# CUSTEFUSE_CM_CORE register map
Vendor: Texas Instruments
Peripheral module from a debugger description file (folder omap5430_ES2_PUBLIC).
Registers are 32-bit, access per field, reset 0x3 unless marked. A register's access mark holds for its fields unless they carry their own. Offsets are as the file gives them; lines under a group give offsets from that group; [hi:lo] are bit positions; {n}, {i} and the like mark numbered series; 'fields as' and 'values as' point back to an identical list; <NAME> marks a mode.

## CUSTEFUSE_CM_CORE
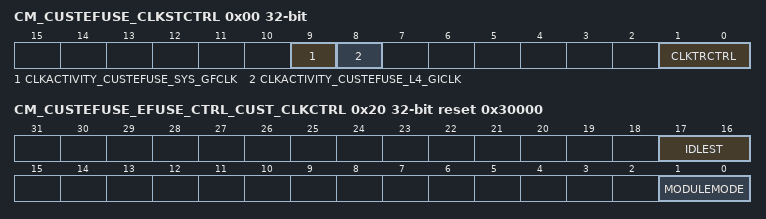
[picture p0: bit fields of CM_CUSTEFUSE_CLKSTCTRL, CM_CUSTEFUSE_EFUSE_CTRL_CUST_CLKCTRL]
0x00 CM_CUSTEFUSE_CLKSTCTRL — This register enables the domain power state transition. It controls the HW supervised domain power state transition between ON-ACTIVE and ON-INACTIVE states. It also hold one status bit per clock input of the domain.
  [9] CLKACTIVITY_CUSTEFUSE_SYS_GFCLK ro — This field indicates the state of the CUSTEFUSE_SYS_GFCLK clock input of the domain. [warm reset insensitive]
    1=Act (Corresponding clock is running or gating/ungating transition is on-going); 0=Inact (Corresponding clock is definitely gated)
  [8] CLKACTIVITY_CUSTEFUSE_L4_GICLK ro — This field indicates the state of the CUSTEFUSE_L4_GICLK clock input of the domain. [warm reset insensitive]
    values as CLKACTIVITY_CUSTEFUSE_SYS_GFCLK
  [1:0] CLKTRCTRL rw — Controls the clock state transition of the EFUSE_CTRL_CUST clock domain.
    0=NO_SLEEP (NO_SLEEP: Sleep transition cannot be initiated. Wakeup transition may however occur.); 3=HW_AUTO (HW_AUTO: Automatic transition is enabled. Sleep and wakeup transition are based upon hardware conditions.); 2=SW_WKUP (SW_WKUP: Start a software forced wake-up transition on the domain.)
0x20 CM_CUSTEFUSE_EFUSE_CTRL_CUST_CLKCTRL reset 0x30000 — This register manages the EFUSE_CTRL_CUST clocks.
  [17:16] IDLEST ro — Module idle status. [warm reset insensitive]
    3=Disable (Module is disabled and cannot be accessed); 2=Idle (Module is in Idle mode (only Interconnect part). It is functional if using separate functional clock); 1=Trans (Module is performing transition: wakeup, or sleep, or sleep abortion); 0=Func (Module is fully functional, including Interconnect)
  [1:0] MODULEMODE rw — Control the way mandatory clocks are managed.
    0=DISABLED (Module is disabled by SW. Any Interconnect access to module results in an error, except if resulting from a module wakeup (asynchronous wakeup).); 2=ENABLE (Module is explicitly enabled. Interface clock (if not used for functions) may be gated according to the clock domain state. Functional clocks are guarantied to stay present. As long as in this configuration, power domain sleep transition cannot happen.)
